AUTOSAR XML (schema 00046)
package /AUTOSAR/EcuM_swc
  mode declaration group EcuM_Mode: initial-mode=STARTUP
    5 x mode:
      STARTUP
      RUN
      POST_RUN
      SHUTDOWN
      SLEEP
  data type mapping set EcuM_Mode_DataTypeMappingSet: mode-request-type-map{implementation-data-type=ecum_state_t, mode-group=EcuM_Mode}  # Data Mapping for the Mode Declaration Group EcuM_Mode.
package /AUTOSAR/EcuM_swc/DataTypes
  6 x impl type, all with category=TYPE_REFERENCE:
    EcuM_UserType: range raw 0..255, implementation-data-type=uint8
    EcuM_TimeType: range raw 0..4294967295, implementation-data-type=uint32
    EcuM_BootTargetType: compu {0=ECUM_BOOT_TARGET_APP, 1=ECUM_BOOT_TARGET_OEM_BOOTLOADER, 2=ECUM_BOOT_TARGET_SYS_BOOTLOADER}, range raw 0..2, implementation-data-type=uint8
    EcuM_ShutdownCauseType: compu {0=ECUM_CAUSE_UNKNOWN, 1=ECUM_CAUSE_ECU_STATE, 2=ECUM_CAUSE_WDGM, 3=ECUM_CAUSE_DCM}, range raw 0..3, implementation-data-type=uint8
    EcuM_ShutdownModeType: compu {0=EcuMSleepMode, 256=Conf_ECUM_RESET_MCU}, range raw 0..4294967295, implementation-data-type=uint16
    EcuM_ShutdownTargetType: compu {0=ECUM_SHUTDOWN_TARGET_SLEEP, 1=ECUM_SHUTDOWN_TARGET_RESET, 2=ECUM_SHUTDOWN_TARGET_OFF}, range raw 0..255, implementation-data-type=uint8
package /AUTOSAR/EcuM_swc/Interfaces
  mode switch interface EcuM_CurrentMode: is-service=true, service-kind=ECU-MANAGER
    mode group currentMode: type=EcuM_Mode
  4 x client server interface, all with is-service=true, service-kind=ECU-MANAGER:
    EcuM_ShutdownTarget
      5 x operation, all with possible-error=[EcuM_ShutdownTarget/E_OK, EcuM_ShutdownTarget/E_NOT_OK]:
        GetLastShutdownTarget
          arg shutdownTarget: type=EcuM_ShutdownTargetType, direction=OUT
          arg shutdownMode: type=EcuM_ShutdownModeType, direction=OUT
        GetShutdownCause
          arg shutdownCause: type=EcuM_ShutdownCauseType, direction=OUT
        GetShutdownTarget
          arg shutdownTarget: type=EcuM_ShutdownTargetType, direction=OUT
          arg shutdownMode: type=EcuM_ShutdownModeType, direction=OUT
        SelectShutdownCause
          arg shutdownCause: type=EcuM_ShutdownCauseType, direction=IN
        SelectShutdownTarget
          arg shutdownTarget: type=EcuM_ShutdownTargetType, direction=IN
          arg shutdownMode: type=EcuM_ShutdownModeType, direction=IN
      error E_OK: error-code=0
      error E_NOT_OK: error-code=1
    EcuM_BootTarget
      operation GetBootTarget: possible-error=EcuM_BootTarget/E_OK
        arg target: type=EcuM_BootTargetType, direction=OUT
      operation SelectBootTarget: possible-error=[EcuM_BootTarget/E_OK, EcuM_BootTarget/E_NOT_OK]
        arg target: type=EcuM_BootTargetType, direction=IN
      error E_OK: error-code=0
      error E_NOT_OK: error-code=1
    EcuM_Time
      operation GetCurrentTime: possible-error=[EcuM_Time/E_OK, EcuM_Time/E_NOT_OK]
        arg time: type=EcuM_TimeType, direction=OUT
      operation GetWakeupTime: possible-error=[EcuM_Time/E_OK, EcuM_Time/E_NOT_OK]
        arg time: type=EcuM_TimeType, direction=OUT
      error E_OK: error-code=0
      error E_NOT_OK: error-code=1
    EcuM_StateRequest
      4 x operation, all with possible-error=[EcuM_StateRequest/E_OK, EcuM_StateRequest/E_NOT_OK]:
        ReleasePOSTRUN
        ReleaseRUN
        RequestPOSTRUN
        RequestRUN
      error E_OK: error-code=0
      error E_NOT_OK: error-code=1
package /AUTOSAR/EcuM_swc/ComponentTypes
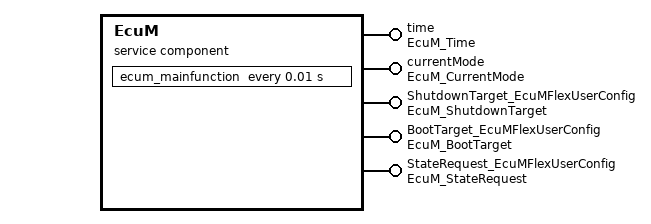
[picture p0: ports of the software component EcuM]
  service sw component type EcuM: category=SERVICE_COMPONENT
    5 x provide port:
      time: provided-interface=EcuM_Time
      currentMode: provided-interface=EcuM_CurrentMode
      ShutdownTarget_EcuMFlexUserConfig: provided-interface=EcuM_ShutdownTarget
      BootTarget_EcuMFlexUserConfig: provided-interface=EcuM_BootTarget
      StateRequest_EcuMFlexUserConfig: provided-interface=EcuM_StateRequest
    behavior EcuMInternalBehavior: data-type-mapping=EcuM_Mode_DataTypeMappingSet, handle-termination-and-restart=NO-SUPPORT, included-data-type-set=data-type=[ecum_state_t, ecum_shutdown_mode_t, ecum_time_t, ecum_user_t, ecum_shutdown_cause_t, ecum_boot_target_t]
      timing event Timer_EcuM_MainFunction: start-on-event=ecum_mainfunction, period=0.01
      13 x operation invoked event:
        OpEventGetCurrentTime_GetCurrentTime_time: start-on-event=GetCurrentTime, operation=time.GetCurrentTime
        OpEventGetWakeupTime_GetWakeupTime_time: start-on-event=GetWakeupTime, operation=time.GetWakeupTime
        OpEventGetLastShutdownTarget_GetLastShutdownTarget_ShutdownTarget_EcuMFlexUserConfig: start-on-event=GetLastShutdownTarget, operation=ShutdownTarget_EcuMFlexUserConfig.GetLastShutdownTarget
        OpEventGetShutdownCause_GetShutdownCause_ShutdownTarget_EcuMFlexUserConfig: start-on-event=GetShutdownCause, operation=ShutdownTarget_EcuMFlexUserConfig.GetShutdownCause
        OpEventGetShutdownTarget_GetShutdownTarget_ShutdownTarget_EcuMFlexUserConfig: start-on-event=GetShutdownTarget, operation=ShutdownTarget_EcuMFlexUserConfig.GetShutdownTarget
        OpEventSelectShutdownCause_SelectShutdownCause_ShutdownTarget_EcuMFlexUserConfig: start-on-event=SelectShutdownCause, operation=ShutdownTarget_EcuMFlexUserConfig.SelectShutdownCause
        OpEventSelectShutdownTarget_SelectShutdownTarget_ShutdownTarget_EcuMFlexUserConfig: start-on-event=SelectShutdownTarget, operation=ShutdownTarget_EcuMFlexUserConfig.SelectShutdownTarget
        OpEventGetBootTarget_GetBootTarget_BootTarget_EcuMFlexUserConfig: start-on-event=GetBootTarget, operation=BootTarget_EcuMFlexUserConfig.GetBootTarget
        OpEventSelectBootTarget_SelectBootTarget_BootTarget_EcuMFlexUserConfig: start-on-event=SelectBootTarget, operation=BootTarget_EcuMFlexUserConfig.SelectBootTarget
        OpEventReleasePOSTRUN_ReleasePOSTRUN_StateRequest_EcuMFlexUserConfig: start-on-event=ReleasePOSTRUN, operation=StateRequest_EcuMFlexUserConfig.ReleasePOSTRUN
        OpEventReleaseRUN_ReleaseRUN_StateRequest_EcuMFlexUserConfig: start-on-event=ReleaseRUN, operation=StateRequest_EcuMFlexUserConfig.ReleaseRUN
        OpEventRequestPOSTRUN_RequestPOSTRUN_StateRequest_EcuMFlexUserConfig: start-on-event=RequestPOSTRUN, operation=StateRequest_EcuMFlexUserConfig.RequestPOSTRUN
        OpEventRequestRUN_RequestRUN_StateRequest_EcuMFlexUserConfig: start-on-event=RequestRUN, operation=StateRequest_EcuMFlexUserConfig.RequestRUN
      port-api-options:
        enable-take-address=true, indirect-api=false, port=time
        enable-take-address=true, indirect-api=false, port=currentMode
        enable-take-address=true, indirect-api=false, port=ShutdownTarget_EcuMFlexUserConfig
        enable-take-address=true, indirect-api=false, port=BootTarget_EcuMFlexUserConfig
        {enable-take-address=true, indirect-api=false, port-defined-argument-value{value=0, value-type=EcuM_UserType}, port=StateRequest_EcuMFlexUserConfig}
      14 x runnable:
        ecum_mainfunction
          mode switch point SWITCH_currentMode_EcuM_Mode: mode-group=currentMode.currentMode
        GetLastShutdownTarget: can-be-invoked-concurrently=true, symbol=EcuM_GetLastShutdownTarget
        GetShutdownCause: can-be-invoked-concurrently=true, symbol=EcuM_GetShutdownCause
        GetShutdownTarget: can-be-invoked-concurrently=true, symbol=EcuM_GetShutdownTarget
        SelectShutdownCause: can-be-invoked-concurrently=true, symbol=EcuM_SelectShutdownCause
        SelectShutdownTarget: can-be-invoked-concurrently=true, symbol=EcuM_SelectShutdownTarget
        GetBootTarget: can-be-invoked-concurrently=true, symbol=EcuM_GetBootTarget
        SelectBootTarget: can-be-invoked-concurrently=true, symbol=EcuM_SelectBootTarget
        GetCurrentTime: can-be-invoked-concurrently=true, symbol=EcuM_GetCurrentTime
        GetWakeupTime: can-be-invoked-concurrently=true, symbol=EcuM_GetWakeupTime
        ReleasePOSTRUN: can-be-invoked-concurrently=true, symbol=EcuM_ReleasePOST_RUN
        ReleaseRUN: can-be-invoked-concurrently=true, symbol=EcuM_ReleaseRUN
        RequestPOSTRUN: can-be-invoked-concurrently=true, symbol=EcuM_RequestPOST_RUN
        RequestRUN: can-be-invoked-concurrently=true, symbol=EcuM_RequestRUN
  swc implementation EcuMImplementation: programming-language=C, behavior=EcuMInternalBehavior
